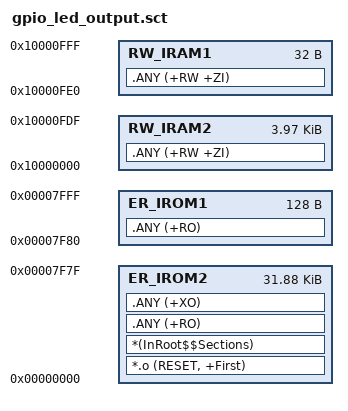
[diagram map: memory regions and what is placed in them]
; *************************************************************
; *** Scatter-Loading Description File generated by uVision ***
; *************************************************************

LR_IROM2 0x00000000 0x00007F80  {    ; load region size_region
  ER_IROM2 0x00000000 0x00007F80  {  ; load address = execution address
   *.o (RESET, +First)
   *(InRoot$$Sections)
   .ANY (+RO)
   .ANY (+XO)
  }
  RW_IRAM1 0x10000FE0 0x00000020  {  ; RW data
   .ANY (+RW +ZI)
  }
  RW_IRAM2 0x10000000 0x00000FE0  {
   .ANY (+RW +ZI)
  }
}

LR_IROM1 0x00007F80 0x00000080  {
  ER_IROM1 0x00007F80 0x00000080  {  ; load address = execution address
   .ANY (+RO)
  }
}
